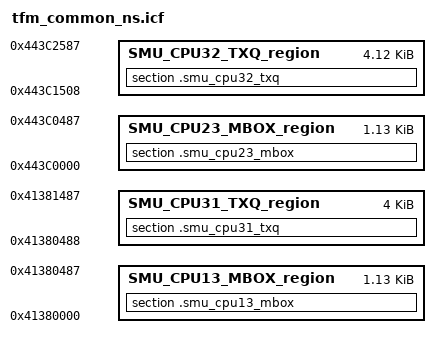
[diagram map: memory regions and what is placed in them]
/*
 * Copyright (c) 2022 Arm Limited
 * Copyright (c) 2021 IAR Systems AB
 *
 * Licensed under the Apache License, Version 2.0 (the "License");
 * you may not use this file except in compliance with the License.
 * You may obtain a copy of the License at
 *
 *     http://www.apache.org/licenses/LICENSE-2.0
 *
 * Unless required by applicable law or agreed to in writing, software
 * distributed under the License is distributed on an "AS IS" BASIS,
 * WITHOUT WARRANTIES OR CONDITIONS OF ANY KIND, either express or implied.
 * See the License for the specific language governing permissions and
 * limitations under the License.
 *
 */
// NXP : Based on platform/ext/common/iar/tfm_common_ns.icf

/* Linker script to configure memory regions. */
/* This file will be run trough the pre-processor. */

#include "region_defs.h"

define block ER_CODE            with fixed order, alignment = 8 {
       section .intvec,
       readonly};
define block LR_CODE with fixed order {block ER_CODE};
place at address NS_CODE_START {block LR_CODE};

define block ER_DATA	        with alignment = 8 {readwrite};
define block CSTACK             with alignment = 32, size = NS_STACK_SIZE { };
define block HEAP               with alignment = 8, size = NS_HEAP_SIZE { };
define block ARM_LIB_HEAP       with alignment = 8, size = NS_HEAP_SIZE { };
define overlay HEAP_OVL         {block HEAP};
define overlay HEAP_OVL         {block ARM_LIB_HEAP};
keep {block CSTACK, block HEAP, block ARM_LIB_HEAP};

do not initialize  { section .noinit };
initialize by copy { readwrite };
if (isdefinedsymbol(__USE_DLIB_PERTHREAD))
{
  // Required in a multi-threaded application
  initialize by copy with packing = none { section __DLIB_PERTHREAD };
}

define block DATA with fixed order, maximum size = NS_DATA_SIZE  {
       block ER_DATA,
       block CSTACK,
       overlay HEAP_OVL
};
place at address NS_DATA_START {block DATA};
// --------- NXP --------------
/* This regions map to connectivity peripherals and are required for Wi-Fi to
 * operate properly in NSPE.
 */
define symbol m_mbox1_start         = 0x41380000;
define symbol m_mbox1_end           = 0x41380487;
define symbol m_txq1_start          = 0x41380488;
define symbol m_txq1_end            = 0x41381487;
define symbol m_mbox2_start         = 0x443C0000;
define symbol m_mbox2_end           = 0x443C0487;
define symbol m_txq23_start         = 0x443C0488;
define symbol m_txq23_end           = 0x443C1507;
define symbol m_txq32_start         = 0x443C1508;
define symbol m_txq32_end           = 0x443C2587;

define region SMU_CPU13_MBOX_region = mem:[from m_mbox1_start to m_mbox1_end];
define region SMU_CPU31_TXQ_region  = mem:[from m_txq1_start to m_txq1_end];
define region SMU_CPU23_MBOX_region = mem:[from m_mbox2_start to m_mbox2_end];
define region SMU_CPU32_TXQ_region  = mem:[from m_txq32_start to m_txq32_end];

/* CPU3 <-> CPU1 mailbox */
place in SMU_CPU13_MBOX_region      { section .smu_cpu13_mbox };
/* CPU3 -> CPU1 TXQ */
place in SMU_CPU31_TXQ_region       { section .smu_cpu31_txq };
/* CPU3 <-> CPU2 mailbox */
place in SMU_CPU23_MBOX_region      { section .smu_cpu23_mbox };
/* CPU3 -> CPU2 TXQ */
place in SMU_CPU32_TXQ_region       { section .smu_cpu32_txq };
// --------- NXP end --------------
